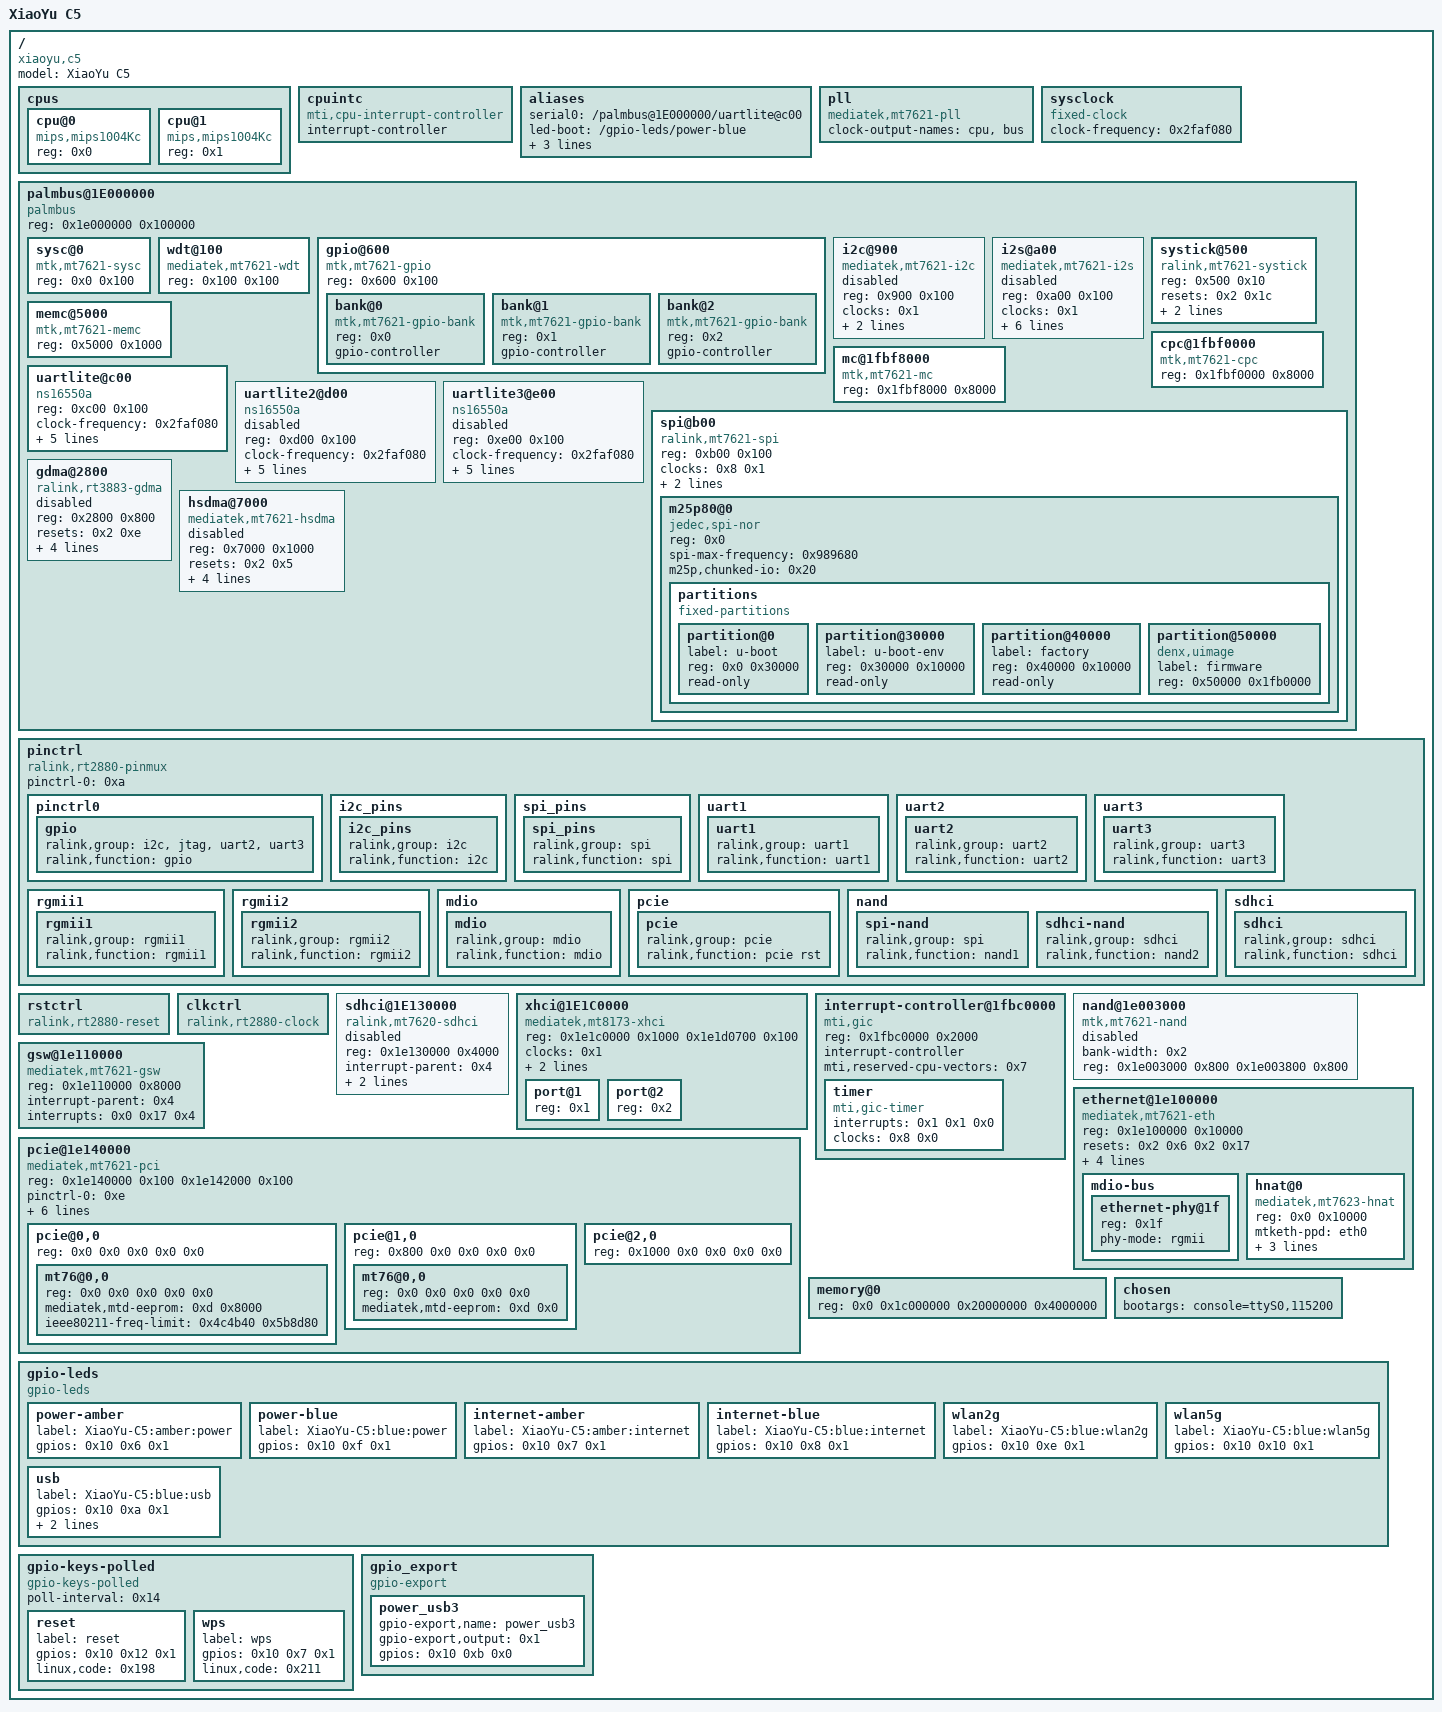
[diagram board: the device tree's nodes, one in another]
/dts-v1/;

/ {
	#address-cells = <0x1>;
	#size-cells = <0x1>;
	compatible = "xiaoyu,c5", "mediatek,mt7621-eval-board", "mediatek,mt7621-soc";
	model = "XiaoYu C5";

	cpus {
		#address-cells = <0x1>;
		#size-cells = <0x0>;

		cpu@0 {
			device_type = "cpu";
			compatible = "mips,mips1004Kc";
			reg = <0x0>;
		};

		cpu@1 {
			device_type = "cpu";
			compatible = "mips,mips1004Kc";
			reg = <0x1>;
		};
	};

	cpuintc {
		#address-cells = <0x0>;
		#interrupt-cells = <0x1>;
		interrupt-controller;
		compatible = "mti,cpu-interrupt-controller";
	};

	aliases {
		serial0 = "/palmbus@1E000000/uartlite@c00";
		led-boot = "/gpio-leds/power-blue";
		led-failsafe = "/gpio-leds/power-blue";
		led-running = "/gpio-leds/power-blue";
		led-upgrade = "/gpio-leds/power-blue";
	};

	pll {
		compatible = "mediatek,mt7621-pll", "syscon";
		#clock-cells = <0x1>;
		clock-output-names = "cpu", "bus";
		linux,phandle = <0x8>;
		phandle = <0x8>;
	};

	sysclock {
		#clock-cells = <0x0>;
		compatible = "fixed-clock";
		clock-frequency = <0x2faf080>;
		linux,phandle = <0x1>;
		phandle = <0x1>;
	};

	palmbus@1E000000 {
		compatible = "palmbus";
		reg = <0x1e000000 0x100000>;
		ranges = <0x0 0x1e000000 0xfffff>;
		#address-cells = <0x1>;
		#size-cells = <0x1>;

		sysc@0 {
			compatible = "mtk,mt7621-sysc";
			reg = <0x0 0x100>;
		};

		wdt@100 {
			compatible = "mediatek,mt7621-wdt";
			reg = <0x100 0x100>;
		};

		gpio@600 {
			#address-cells = <0x1>;
			#size-cells = <0x0>;
			compatible = "mtk,mt7621-gpio";
			reg = <0x600 0x100>;

			bank@0 {
				reg = <0x0>;
				compatible = "mtk,mt7621-gpio-bank";
				gpio-controller;
				#gpio-cells = <0x2>;
				linux,phandle = <0x10>;
				phandle = <0x10>;
			};

			bank@1 {
				reg = <0x1>;
				compatible = "mtk,mt7621-gpio-bank";
				gpio-controller;
				#gpio-cells = <0x2>;
			};

			bank@2 {
				reg = <0x2>;
				compatible = "mtk,mt7621-gpio-bank";
				gpio-controller;
				#gpio-cells = <0x2>;
			};
		};

		i2c@900 {
			compatible = "mediatek,mt7621-i2c";
			reg = <0x900 0x100>;
			clocks = <0x1>;
			resets = <0x2 0x10>;
			reset-names = "i2c";
			#address-cells = <0x1>;
			#size-cells = <0x0>;
			status = "disabled";
			pinctrl-names = "default";
			pinctrl-0 = <0x3>;
		};

		i2s@a00 {
			compatible = "mediatek,mt7621-i2s";
			reg = <0xa00 0x100>;
			clocks = <0x1>;
			resets = <0x2 0x11>;
			reset-names = "i2s";
			interrupt-parent = <0x4>;
			interrupts = <0x0 0x10 0x4>;
			txdma-req = <0x2>;
			rxdma-req = <0x3>;
			dmas = <0x5 0x4 0x5 0x6>;
			dma-names = "tx", "rx";
			status = "disabled";
		};

		systick@500 {
			compatible = "ralink,mt7621-systick", "ralink,cevt-systick";
			reg = <0x500 0x10>;
			resets = <0x2 0x1c>;
			reset-names = "intc";
			interrupt-parent = <0x4>;
			interrupts = <0x0 0x5 0x4>;
		};

		memc@5000 {
			compatible = "mtk,mt7621-memc";
			reg = <0x5000 0x1000>;
		};

		cpc@1fbf0000 {
			compatible = "mtk,mt7621-cpc";
			reg = <0x1fbf0000 0x8000>;
		};

		mc@1fbf8000 {
			compatible = "mtk,mt7621-mc";
			reg = <0x1fbf8000 0x8000>;
		};

		uartlite@c00 {
			compatible = "ns16550a";
			reg = <0xc00 0x100>;
			clock-frequency = <0x2faf080>;
			interrupt-parent = <0x4>;
			interrupts = <0x0 0x1a 0x4>;
			reg-shift = <0x2>;
			reg-io-width = <0x4>;
			no-loopback-test;
		};

		uartlite2@d00 {
			compatible = "ns16550a";
			reg = <0xd00 0x100>;
			clock-frequency = <0x2faf080>;
			interrupt-parent = <0x4>;
			interrupts = <0x0 0x1b 0x4>;
			reg-shift = <0x2>;
			reg-io-width = <0x4>;
			pinctrl-names = "default";
			pinctrl-0 = <0x6>;
			status = "disabled";
		};

		uartlite3@e00 {
			compatible = "ns16550a";
			reg = <0xe00 0x100>;
			clock-frequency = <0x2faf080>;
			interrupt-parent = <0x4>;
			interrupts = <0x0 0x1c 0x4>;
			reg-shift = <0x2>;
			reg-io-width = <0x4>;
			pinctrl-names = "default";
			pinctrl-0 = <0x7>;
			status = "disabled";
		};

		spi@b00 {
			status = "okay";
			compatible = "ralink,mt7621-spi";
			reg = <0xb00 0x100>;
			clocks = <0x8 0x1>;
			resets = <0x2 0x12>;
			reset-names = "spi";
			#address-cells = <0x1>;
			#size-cells = <0x0>;
			pinctrl-names = "default";
			pinctrl-0 = <0x9>;

			m25p80@0 {
				compatible = "jedec,spi-nor";
				reg = <0x0>;
				spi-max-frequency = <0x989680>;
				m25p,chunked-io = <0x20>;

				partitions {
					compatible = "fixed-partitions";
					#address-cells = <0x1>;
					#size-cells = <0x1>;

					partition@0 {
						label = "u-boot";
						reg = <0x0 0x30000>;
						read-only;
					};

					partition@30000 {
						label = "u-boot-env";
						reg = <0x30000 0x10000>;
						read-only;
					};

					partition@40000 {
						label = "factory";
						reg = <0x40000 0x10000>;
						read-only;
						linux,phandle = <0xd>;
						phandle = <0xd>;
					};

					partition@50000 {
						compatible = "denx,uimage";
						label = "firmware";
						reg = <0x50000 0x1fb0000>;
					};
				};
			};
		};

		gdma@2800 {
			compatible = "ralink,rt3883-gdma";
			reg = <0x2800 0x800>;
			resets = <0x2 0xe>;
			reset-names = "dma";
			interrupt-parent = <0x4>;
			interrupts = <0x0 0xd 0x4>;
			#dma-cells = <0x1>;
			#dma-channels = <0x10>;
			#dma-requests = <0x10>;
			status = "disabled";
			linux,phandle = <0x5>;
			phandle = <0x5>;
		};

		hsdma@7000 {
			compatible = "mediatek,mt7621-hsdma";
			reg = <0x7000 0x1000>;
			resets = <0x2 0x5>;
			reset-names = "hsdma";
			interrupt-parent = <0x4>;
			interrupts = <0x0 0xb 0x4>;
			#dma-cells = <0x1>;
			#dma-channels = <0x1>;
			#dma-requests = <0x1>;
			status = "disabled";
		};
	};

	pinctrl {
		compatible = "ralink,rt2880-pinmux";
		pinctrl-names = "default";
		pinctrl-0 = <0xa>;

		pinctrl0 {
			linux,phandle = <0xa>;
			phandle = <0xa>;

			gpio {
				ralink,group = "i2c", "jtag", "uart2", "uart3";
				ralink,function = "gpio";
			};
		};

		i2c_pins {
			linux,phandle = <0x3>;
			phandle = <0x3>;

			i2c_pins {
				ralink,group = "i2c";
				ralink,function = "i2c";
			};
		};

		spi_pins {
			linux,phandle = <0x9>;
			phandle = <0x9>;

			spi_pins {
				ralink,group = "spi";
				ralink,function = "spi";
			};
		};

		uart1 {

			uart1 {
				ralink,group = "uart1";
				ralink,function = "uart1";
			};
		};

		uart2 {
			linux,phandle = <0x6>;
			phandle = <0x6>;

			uart2 {
				ralink,group = "uart2";
				ralink,function = "uart2";
			};
		};

		uart3 {
			linux,phandle = <0x7>;
			phandle = <0x7>;

			uart3 {
				ralink,group = "uart3";
				ralink,function = "uart3";
			};
		};

		rgmii1 {

			rgmii1 {
				ralink,group = "rgmii1";
				ralink,function = "rgmii1";
			};
		};

		rgmii2 {

			rgmii2 {
				ralink,group = "rgmii2";
				ralink,function = "rgmii2";
			};
		};

		mdio {

			mdio {
				ralink,group = "mdio";
				ralink,function = "mdio";
			};
		};

		pcie {
			linux,phandle = <0xe>;
			phandle = <0xe>;

			pcie {
				ralink,group = "pcie";
				ralink,function = "pcie rst";
			};
		};

		nand {

			spi-nand {
				ralink,group = "spi";
				ralink,function = "nand1";
			};

			sdhci-nand {
				ralink,group = "sdhci";
				ralink,function = "nand2";
			};
		};

		sdhci {
			linux,phandle = <0xb>;
			phandle = <0xb>;

			sdhci {
				ralink,group = "sdhci";
				ralink,function = "sdhci";
			};
		};
	};

	rstctrl {
		compatible = "ralink,rt2880-reset";
		#reset-cells = <0x1>;
		linux,phandle = <0x2>;
		phandle = <0x2>;
	};

	clkctrl {
		compatible = "ralink,rt2880-clock";
		#clock-cells = <0x1>;
		linux,phandle = <0xf>;
		phandle = <0xf>;
	};

	sdhci@1E130000 {
		status = "disabled";
		compatible = "ralink,mt7620-sdhci";
		reg = <0x1e130000 0x4000>;
		interrupt-parent = <0x4>;
		interrupts = <0x0 0x14 0x4>;
		pinctrl-names = "default";
		pinctrl-0 = <0xb>;
	};

	xhci@1E1C0000 {
		#address-cells = <0x1>;
		#size-cells = <0x0>;
		status = "okay";
		compatible = "mediatek,mt8173-xhci";
		reg = <0x1e1c0000 0x1000 0x1e1d0700 0x100>;
		reg-names = "mac", "ippc";
		clocks = <0x1>;
		clock-names = "sys_ck";
		interrupt-parent = <0x4>;
		interrupts = <0x0 0x16 0x4>;

		port@1 {
			reg = <0x1>;
			#trigger-source-cells = <0x0>;
			linux,phandle = <0x11>;
			phandle = <0x11>;
		};

		port@2 {
			reg = <0x2>;
			#trigger-source-cells = <0x0>;
			linux,phandle = <0x12>;
			phandle = <0x12>;
		};
	};

	interrupt-controller@1fbc0000 {
		compatible = "mti,gic";
		reg = <0x1fbc0000 0x2000>;
		interrupt-controller;
		#interrupt-cells = <0x3>;
		mti,reserved-cpu-vectors = <0x7>;
		linux,phandle = <0x4>;
		phandle = <0x4>;

		timer {
			compatible = "mti,gic-timer";
			interrupts = <0x1 0x1 0x0>;
			clocks = <0x8 0x0>;
		};
	};

	nand@1e003000 {
		status = "disabled";
		compatible = "mtk,mt7621-nand";
		bank-width = <0x2>;
		reg = <0x1e003000 0x800 0x1e003800 0x800>;
	};

	ethernet@1e100000 {
		compatible = "mediatek,mt7621-eth";
		reg = <0x1e100000 0x10000>;
		#address-cells = <0x1>;
		#size-cells = <0x1>;
		resets = <0x2 0x6 0x2 0x17>;
		reset-names = "fe", "eth";
		interrupt-parent = <0x4>;
		interrupts = <0x0 0x3 0x4>;
		mediatek,switch = <0xc>;
		mtd-mac-address = <0xd 0xe000>;

		mdio-bus {
			#address-cells = <0x1>;
			#size-cells = <0x0>;

			ethernet-phy@1f {
				reg = <0x1f>;
				phy-mode = "rgmii";
			};
		};

		hnat@0 {
			compatible = "mediatek,mt7623-hnat";
			reg = <0x0 0x10000>;
			mtketh-ppd = "eth0";
			mtketh-lan = "eth0";
			mtketh-wan = "eth0";
			resets = <0x2 0x0>;
			reset-names = "mtketh";
		};
	};

	gsw@1e110000 {
		compatible = "mediatek,mt7621-gsw";
		reg = <0x1e110000 0x8000>;
		interrupt-parent = <0x4>;
		interrupts = <0x0 0x17 0x4>;
		linux,phandle = <0xc>;
		phandle = <0xc>;
	};

	pcie@1e140000 {
		compatible = "mediatek,mt7621-pci";
		reg = <0x1e140000 0x100 0x1e142000 0x100>;
		#address-cells = <0x3>;
		#size-cells = <0x2>;
		pinctrl-names = "default";
		pinctrl-0 = <0xe>;
		device_type = "pci";
		bus-range = <0x0 0xff>;
		ranges = <0x2000000 0x0 0x0 0x60000000 0x0 0x10000000 0x1000000 0x0 0x0 0x1e160000 0x0 0x10000>;
		interrupt-parent = <0x4>;
		interrupts = <0x0 0x4 0x4 0x0 0x18 0x4 0x0 0x19 0x4>;
		status = "okay";
		resets = <0x2 0x18 0x2 0x19 0x2 0x1a>;
		reset-names = "pcie0", "pcie1", "pcie2";
		clocks = <0xf 0x18 0xf 0x19 0xf 0x1a>;
		clock-names = "pcie0", "pcie1", "pcie2";

		pcie@0,0 {
			reg = <0x0 0x0 0x0 0x0 0x0>;
			#address-cells = <0x3>;
			#size-cells = <0x2>;
			ranges;

			mt76@0,0 {
				reg = <0x0 0x0 0x0 0x0 0x0>;
				mediatek,mtd-eeprom = <0xd 0x8000>;
				ieee80211-freq-limit = <0x4c4b40 0x5b8d80>;
			};
		};

		pcie@1,0 {
			reg = <0x800 0x0 0x0 0x0 0x0>;
			#address-cells = <0x3>;
			#size-cells = <0x2>;
			ranges;

			mt76@0,0 {
				reg = <0x0 0x0 0x0 0x0 0x0>;
				mediatek,mtd-eeprom = <0xd 0x0>;
			};
		};

		pcie@2,0 {
			reg = <0x1000 0x0 0x0 0x0 0x0>;
			#address-cells = <0x3>;
			#size-cells = <0x2>;
			ranges;
		};
	};

	memory@0 {
		device_type = "memory";
		reg = <0x0 0x1c000000 0x20000000 0x4000000>;
	};

	chosen {
		bootargs = "console=ttyS0,115200";
	};

	gpio-leds {
		compatible = "gpio-leds";

		power-amber {
			label = "XiaoYu-C5:amber:power";
			gpios = <0x10 0x6 0x1>;
		};

		power-blue {
			label = "XiaoYu-C5:blue:power";
			gpios = <0x10 0xf 0x1>;
		};

		internet-amber {
			label = "XiaoYu-C5:amber:internet";
			gpios = <0x10 0x7 0x1>;
		};

		internet-blue {
			label = "XiaoYu-C5:blue:internet";
			gpios = <0x10 0x8 0x1>;
		};

		wlan2g {
			label = "XiaoYu-C5:blue:wlan2g";
			gpios = <0x10 0xe 0x1>;
		};

		wlan5g {
			label = "XiaoYu-C5:blue:wlan5g";
			gpios = <0x10 0x10 0x1>;
		};

		usb {
			label = "XiaoYu-C5:blue:usb";
			gpios = <0x10 0xa 0x1>;
			trigger-sources = <0x11 0x12>;
			linux,default-trigger = "usbport";
		};
	};

	gpio-keys-polled {
		compatible = "gpio-keys-polled";
		poll-interval = <0x14>;

		reset {
			label = "reset";
			gpios = <0x10 0x12 0x1>;
			linux,code = <0x198>;
		};

		wps {
			label = "wps";
			gpios = <0x10 0x7 0x1>;
			linux,code = <0x211>;
		};
	};

	gpio_export {
		compatible = "gpio-export";
		#size-cells = <0x0>;

		power_usb3 {
			gpio-export,name = "power_usb3";
			gpio-export,output = <0x1>;
			gpios = <0x10 0xb 0x0>;
		};
	};
};
